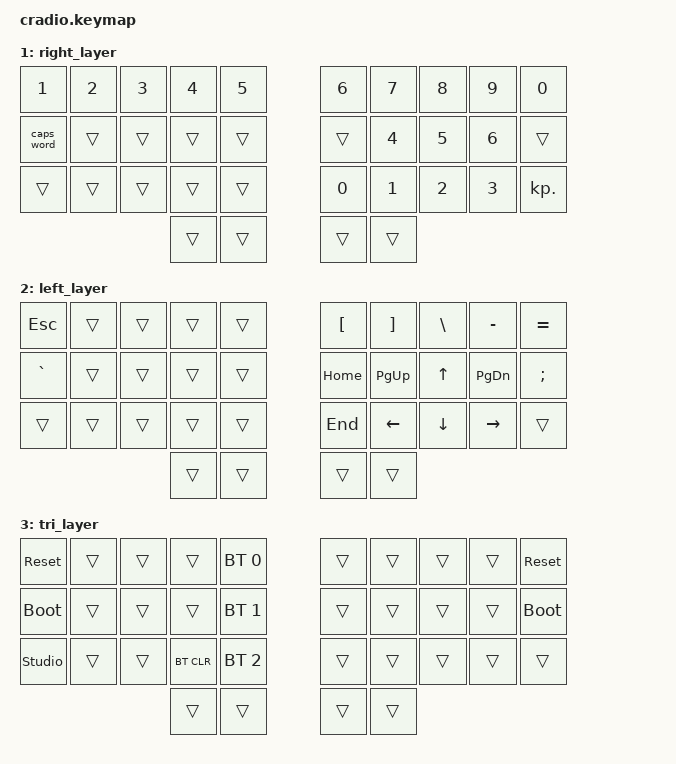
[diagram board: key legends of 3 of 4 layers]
// Copyright (c) 2022 The ZMK Contributors
// SPDX-License-Identifier: MIT

#include <behaviors.dtsi>
#include <dt-bindings/zmk/keys.h>
#include <dt-bindings/zmk/bt.h>

// Home row mods macro
#define HRML(k1,k2,k3,k4,k5) &ht LSHFT k1  &ht LCTRL k2  &ht LALT k3  &ht LGUI k4   &ht GLOBE k5
#define HRMR(k1,k2,k3,k4,k5) &ht GLOBE k1  &ht RGUI k2   &ht RALT k3  &ht RCTRL k4  &ht RSHFT k5

/ {
    behaviors {
        ht: hold_tap {
            compatible = "zmk,behavior-hold-tap";
            #binding-cells = <2>;
            flavor = "tap-preferred";
            tapping-term-ms = <220>;
            quick-tap-ms = <150>;
            require-prior-idle-ms = <100>;
            bindings = <&kp>, <&kp>;
        };
    };

    conditional_layers {
        compatible = "zmk,conditional-layers";
        tri_layer {
            if-layers = <1 2>;
            then-layer = <3>;
        };
    };

    keymap {
        compatible = "zmk,keymap";
        default_layer {
            bindings = <
        //╭──────────┬──────────┬──────────┬──────────┬──────────╮   ╭──────────┬──────────┬──────────┬──────────┬──────────╮
        //│  Q       │  W       │  E       │  R       │  T       │   │  Y       │  U       │  I       │  O       │  P       │
            &kp Q      &kp W      &kp E      &kp R      &kp T          &kp Y      &kp U      &kp I      &kp O      &kp P
        //├──────────┼──────────┼──────────┼──────────┼──────────┤   ├──────────┼──────────┼──────────┼──────────┼──────────┤
        //│  A       │  S       │  D       │  F       │  G       │   │  H       │  J       │  K       │  L       │ ' "      │
           HRML(A,      S,         D,         F,         G)           HRMR(H,      J,         K,         L,        SQT)
        //├──────────┼──────────┼──────────┼──────────┼──────────┤   ├──────────┼──────────┼──────────┼──────────┼──────────┤
        //│  Z       │  X       │  C       │  V       │  B       │   │  N       │  M       │ , <      │ . >      │ / ?      │
            &kp Z      &kp X      &kp C      &kp V      &kp B          &kp N      &kp M      &kp COMMA  &kp DOT    &kp FSLH
        //╰──────────┴──────────┴──────────┼──────────┼──────────┤   ├──────────┼──────────┼──────────┴──────────┴──────────╯
                                            &lt 2 TAB   &kp SPACE     &kp ENTER  &lt 1 BSPC
        //                                 ╰──────────┴──────────╯   ╰──────────┴──────────╯
            >;
        };

        right_layer {
            bindings = <
        //╭──────────┬──────────┬──────────┬──────────┬──────────╮   ╭──────────┬──────────┬──────────┬──────────┬──────────╮
        //│          │          │          │          │          │   │          │          │          │          │          │
            &kp N1     &kp N2     &kp N3     &kp N4     &kp N5         &kp N6     &kp N7     &kp N8     &kp N9     &kp N0
        //├──────────┼──────────┼──────────┼──────────┼──────────┤   ├──────────┼──────────┼──────────┼──────────┼──────────┤
        //│          │          │          │          │          │   │          │          │          │          │          │
           &caps_word  &trans     &trans     &trans     &trans         &trans     &kp N4     &kp N5     &kp N6     &trans   
        //├──────────┼──────────┼──────────┼──────────┼──────────┤   ├──────────┼──────────┼──────────┼──────────┼──────────┤
        //│          │          │          │          │          │   │          │          │          │          │          │
            &trans     &trans     &trans     &trans     &trans         &kp N0     &kp N1     &kp N2     &kp N3     &kp KP_DOT
        //╰──────────┴──────────┴──────────┼──────────┼──────────┤   ├──────────┼──────────┼──────────┴──────────┴──────────╯
                                             &trans     &trans         &trans     &trans
        //                                 ╰──────────┴──────────╯   ╰──────────┴──────────╯
            >;
        };

        left_layer {
            bindings = <
        //╭──────────┬──────────┬──────────┬──────────┬──────────╮   ╭──────────┬──────────┬──────────┬──────────┬──────────╮
        //│          │          │          │          │          │   │          │          │          │          │          │
            &kp ESC    &trans     &trans     &trans     &trans         &kp LBKT   &kp RBKT   &kp BSLH   &kp MINUS   &kp EQUAL
        //├──────────┼──────────┼──────────┼──────────┼──────────┤   ├──────────┼──────────┼──────────┼──────────┼──────────┤
        //│          │          │          │          │          │   │          │          │          │          │          │
            &kp GRAVE  &trans     &trans     &trans     &trans         &kp HOME   &kp PG_UP  &kp UP     &kp PG_DN  &kp SEMI
        //├──────────┼──────────┼──────────┼──────────┼──────────┤   ├──────────┼──────────┼──────────┼──────────┼──────────┤
        //│          │          │          │          │          │   │          │          │          │          │          │
            &trans     &trans     &trans     &trans     &trans         &kp END    &kp LEFT   &kp DOWN   &kp RIGHT  &trans    
        //╰──────────┴──────────┴──────────┼──────────┼──────────┤   ├──────────┼──────────┼──────────┴──────────┴──────────╯
                                             &trans     &trans         &trans     &trans
        //                                 ╰──────────┴──────────╯   ╰──────────┴──────────╯
            >;
        };

        tri_layer {
            bindings = <
        //╭──────────┬──────────┬──────────┬──────────┬──────────╮   ╭──────────┬──────────┬──────────┬──────────┬──────────╮
        //│ RESET    │          │          │          │PROFILE 0 │   │          │          │          │          │  RESET   │
           &sys_reset  &trans     &trans     &trans    &bt BT_SEL 0    &trans     &trans     &trans     &trans    &sys_reset
        //├──────────┼──────────┼──────────┼──────────┼──────────┤   ├──────────┼──────────┼──────────┼──────────┼──────────┤
        //│BOOTLOADER│          │          │          │PROFILE 1 │   │          │          │          │          │BOOTLOADER│
          &bootloader  &trans     &trans     &trans    &bt BT_SEL 1    &trans     &trans     &trans     &trans    &bootloader
        //├──────────┼──────────┼──────────┼──────────┼──────────┤   ├──────────┼──────────┼──────────┼──────────┼──────────┤
        //│          │          │          │ CLEAR BT │PROFILE 2 │   │          │          │          │          │          │
        &studio_unlock &trans     &trans    &bt BT_CLR &bt BT_SEL 2    &trans     &trans     &trans     &trans     &trans
        //╰──────────┴──────────┴──────────┼──────────┼──────────┤   ├──────────┼──────────┼──────────┴──────────┴──────────╯
                                             &trans     &trans         &trans     &trans
        //                                 ╰──────────┴──────────╯   ╰──────────┴──────────╯
            >;
        };
    };
};
